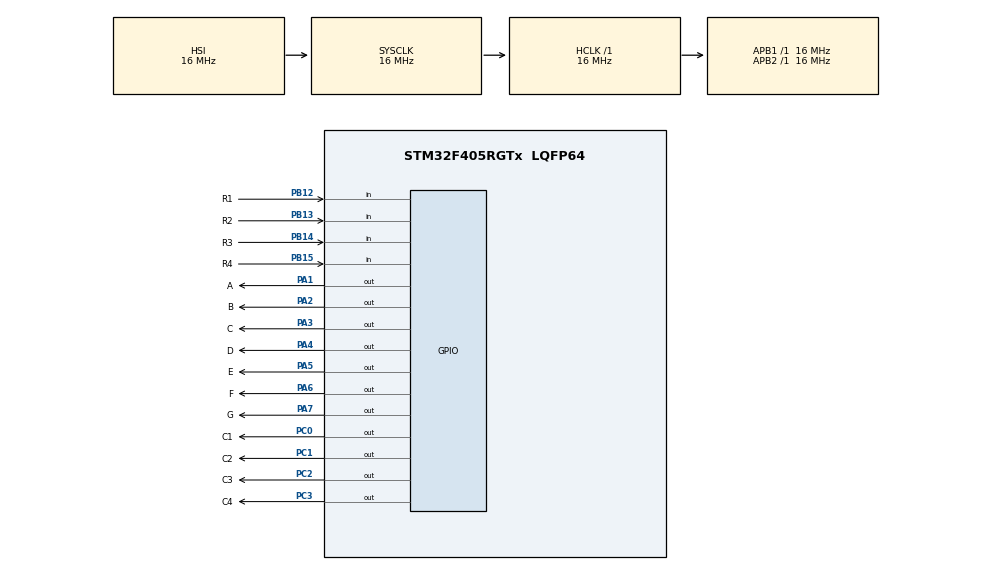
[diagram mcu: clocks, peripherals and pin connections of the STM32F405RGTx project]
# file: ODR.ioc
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Mcu.Family=STM32F4
Mcu.Name=STM32F405RGTx
Mcu.Package=LQFP64
NVIC.PriorityGroup=NVIC_PRIORITYGROUP_4
PA1.GPIO_Label=A
PA1.Signal=GPIO_Output
PA13.Mode=Serial_Wire
PA13.Signal=SYS_JTMS-SWDIO
PA14.Mode=Serial_Wire
PA14.Signal=SYS_JTCK-SWCLK
PA2.GPIO_Label=B
PA2.Signal=GPIO_Output
PA3.GPIO_Label=C
PA3.Signal=GPIO_Output
PA4.GPIO_Label=D
PA4.Signal=GPIO_Output
PA5.GPIO_Label=E
PA5.Signal=GPIO_Output
PA6.GPIO_Label=F
PA6.Signal=GPIO_Output
PA7.GPIO_Label=G
PA7.Signal=GPIO_Output
PB12.GPIO_Label=R1
PB12.Signal=GPIO_Input
PB13.GPIO_Label=R2
PB13.Signal=GPIO_Input
PB14.GPIO_Label=R3
PB14.Signal=GPIO_Input
PB15.GPIO_Label=R4
PB15.Signal=GPIO_Input
PC0.GPIO_Label=C1
PC0.Signal=GPIO_Output
PC1.GPIO_Label=C2
PC1.Signal=GPIO_Output
PC14-OSC32_IN.Mode=LSE-External-Oscillator
PC14-OSC32_IN.Signal=RCC_OSC32_IN
PC15-OSC32_OUT.Mode=LSE-External-Oscillator
PC15-OSC32_OUT.Signal=RCC_OSC32_OUT
PC2.GPIO_Label=C3
PC2.Signal=GPIO_Output
PC3.GPIO_Label=C4
PC3.Signal=GPIO_Output
PH0-OSC_IN.Mode=HSE-External-Oscillator
PH0-OSC_IN.Signal=RCC_OSC_IN
PH1-OSC_OUT.Mode=HSE-External-Oscillator
PH1-OSC_OUT.Signal=RCC_OSC_OUT
ProjectManager.HeapSize=0x200
ProjectManager.StackSize=0x400
ProjectManager.TargetToolchain=STM32CubeIDE
RCC.AHBFreq_Value=16000000
RCC.APB1Freq_Value=16000000
RCC.APB2Freq_Value=16000000
RCC.CortexFreq_Value=16000000
RCC.HSE_VALUE=25000000
RCC.HSI_VALUE=16000000
RCC.SYSCLKFreq_VALUE=16000000
RCC.VCOOutputFreq_Value=192000000
board=custom

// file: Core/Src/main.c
/* USER CODE BEGIN Header */
/**
  ******************************************************************************
  * @file           : main.c
  * @brief          : Main program body
  ******************************************************************************
  * @attention
  *
  * Copyright (c) 2023 STMicroelectronics.
  * All rights reserved.
  *
  * This software is licensed under terms that can be found in the LICENSE file
  * in the root directory of this software component.
  * If no LICENSE file comes with this software, it is provided AS-IS.
  *
  ******************************************************************************
  */
/* USER CODE END Header */
#include "main.h"

void SystemClock_Config(void);
static void MX_GPIO_Init(void);

int main(void)
{
  /* USER CODE BEGIN 1 */
	unsigned int seg[10]={0X007E,0X000C,0X00B6,0X009F,0X00CD,0X00DB,0X00FB,0X000E,0X00FE,0X00DE};
	unsigned int i;
  /* USER CODE END 1 */

  /* MCU Configuration--------------------------------------------------------*/

  /* Reset of all peripherals, Initializes the Flash interface and the Systick. */
  HAL_Init();

  /* Configure the system clock */
  SystemClock_Config();

  /* Initialize all configured peripherals */
  MX_GPIO_Init();

  /* Infinite loop */
  /* USER CODE BEGIN WHILE */
  while (1)
  {
	  HAL_GPIO_WritePin(GPIOC, C1_Pin, GPIO_PIN_RESET);
	  HAL_GPIO_WritePin(GPIOC, C2_Pin, GPIO_PIN_SET);
	  HAL_GPIO_WritePin(GPIOC, C3_Pin, GPIO_PIN_SET);
	  HAL_GPIO_WritePin(GPIOC, C4_Pin, GPIO_PIN_SET);
	  	 	  	if (!(HAL_GPIO_ReadPin (GPIOB, R1_Pin)))
	  	 	  	{
	  	 	  		for(i=0;i<10;i++)
	  	 	  		{
	  	 	  			GPIOA->ODR=seg[i];
	  	 	  		}

	  	 	  	}
	  	        /* if (!(HAL_GPIO_ReadPin (GPIOB,R2_Pin)))
	  	 	    {
	  	 	      	  	while (!(HAL_GPIO_ReadPin (GPIOB,R2_Pin)));
	  	 	      	  GPIOA->ODR = seg[2];
	  	 	      	    }
	  	 	    if (!(HAL_GPIO_ReadPin (GPIOB, R3_Pin)))
	  	 	    {
	  	 	    	  	while (!(HAL_GPIO_ReadPin (GPIOB,R3_Pin)));
	  	 	     	  	GPIOA->ODR = seg[3];
	  	 	    }
	  	 	    if (!(HAL_GPIO_ReadPin (GPIOB, R4_Pin)))
	  	 	    {
	  	 	    	   while (!(HAL_GPIO_ReadPin (GPIOB, R4_Pin)));
	  	 	    	   GPIOA->ODR = seg[4];
	  	 	     }*/
    /* USER CODE END WHILE */

  }
}

void SystemClock_Config(void)
{
  RCC_OscInitTypeDef RCC_OscInitStruct = {0};
  RCC_ClkInitTypeDef RCC_ClkInitStruct = {0};

  /** Configure the main internal regulator output voltage
  */
  __HAL_RCC_PWR_CLK_ENABLE();
  __HAL_PWR_VOLTAGESCALING_CONFIG(PWR_REGULATOR_VOLTAGE_SCALE1);

  /** Initializes the RCC Oscillators according to the specified parameters
  * in the RCC_OscInitTypeDef structure.
  */
  RCC_OscInitStruct.OscillatorType = RCC_OSCILLATORTYPE_HSI;
  RCC_OscInitStruct.HSIState = RCC_HSI_ON;
  RCC_OscInitStruct.HSICalibrationValue = RCC_HSICALIBRATION_DEFAULT;
  RCC_OscInitStruct.PLL.PLLState = RCC_PLL_NONE;
  if (HAL_RCC_OscConfig(&RCC_OscInitStruct) != HAL_OK)
  {
    Error_Handler();
  }

  /** Initializes the CPU, AHB and APB buses clocks
  */
  RCC_ClkInitStruct.ClockType = RCC_CLOCKTYPE_HCLK|RCC_CLOCKTYPE_SYSCLK
                              |RCC_CLOCKTYPE_PCLK1|RCC_CLOCKTYPE_PCLK2;
  RCC_ClkInitStruct.SYSCLKSource = RCC_SYSCLKSOURCE_HSI;
  RCC_ClkInitStruct.AHBCLKDivider = RCC_SYSCLK_DIV1;
  RCC_ClkInitStruct.APB1CLKDivider = RCC_HCLK_DIV1;
  RCC_ClkInitStruct.APB2CLKDivider = RCC_HCLK_DIV1;

  if (HAL_RCC_ClockConfig(&RCC_ClkInitStruct, FLASH_LATENCY_0) != HAL_OK)
  {
    Error_Handler();
  }
}

static void MX_GPIO_Init(void)
{
  GPIO_InitTypeDef GPIO_InitStruct = {0};

  /* GPIO Ports Clock Enable */
  __HAL_RCC_GPIOC_CLK_ENABLE();
  __HAL_RCC_GPIOH_CLK_ENABLE();
  __HAL_RCC_GPIOA_CLK_ENABLE();
  __HAL_RCC_GPIOB_CLK_ENABLE();

  /*Configure GPIO pin Output Level */
  HAL_GPIO_WritePin(GPIOC, C1_Pin|C2_Pin|C3_Pin|C4_Pin, GPIO_PIN_RESET);

  /*Configure GPIO pin Output Level */
  HAL_GPIO_WritePin(GPIOA, A_Pin|B_Pin|C_Pin|D_Pin
                          |E_Pin|F_Pin|G_Pin, GPIO_PIN_RESET);

  /*Configure GPIO pins : C1_Pin C2_Pin C3_Pin C4_Pin */
  GPIO_InitStruct.Pin = C1_Pin|C2_Pin|C3_Pin|C4_Pin;
  GPIO_InitStruct.Mode = GPIO_MODE_OUTPUT_PP;
  GPIO_InitStruct.Pull = GPIO_NOPULL;
  GPIO_InitStruct.Speed = GPIO_SPEED_FREQ_LOW;
  HAL_GPIO_Init(GPIOC, &GPIO_InitStruct);

  /*Configure GPIO pins : A_Pin B_Pin C_Pin D_Pin
                           E_Pin F_Pin G_Pin */
  GPIO_InitStruct.Pin = A_Pin|B_Pin|C_Pin|D_Pin
                          |E_Pin|F_Pin|G_Pin;
  GPIO_InitStruct.Mode = GPIO_MODE_OUTPUT_PP;
  GPIO_InitStruct.Pull = GPIO_NOPULL;
  GPIO_InitStruct.Speed = GPIO_SPEED_FREQ_LOW;
  HAL_GPIO_Init(GPIOA, &GPIO_InitStruct);

  /*Configure GPIO pins : R1_Pin R2_Pin R3_Pin R4_Pin */
  GPIO_InitStruct.Pin = R1_Pin|R2_Pin|R3_Pin|R4_Pin;
  GPIO_InitStruct.Mode = GPIO_MODE_INPUT;
  GPIO_InitStruct.Pull = GPIO_NOPULL;
  HAL_GPIO_Init(GPIOB, &GPIO_InitStruct);

}

void Error_Handler(void)
{
  __disable_irq();
  while (1)
  {
  }
}
